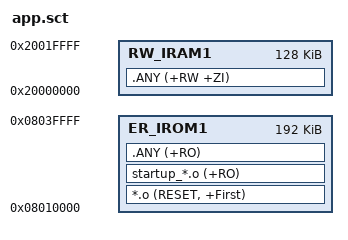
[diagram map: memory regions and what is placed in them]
LR_IROM1 0x08010000 0x00030000  {    ; App A: 192KB, 起始地址 0x0801 0000
  ER_IROM1 0x08010000 0x00030000  {
    *.o (RESET, +First)
    startup_*.o (+RO)
    .ANY (+RO)
  }
  RW_IRAM1 0x20000000 0x00020000  {  ; 128KB SRAM
    .ANY (+RW +ZI)
  }
}
